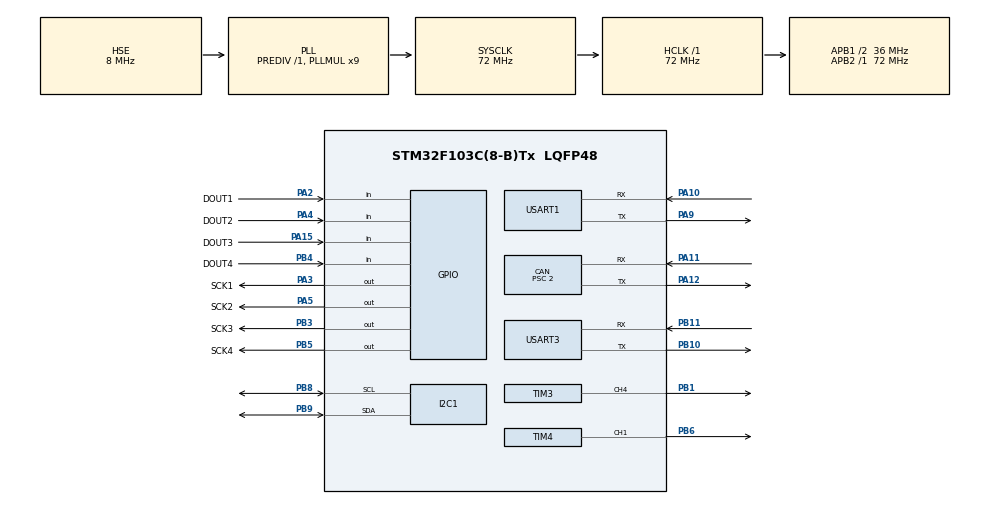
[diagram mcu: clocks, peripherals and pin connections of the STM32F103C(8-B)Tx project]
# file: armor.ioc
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CAN.BS1=CAN_BS1_15TQ
CAN.BS2=CAN_BS2_2TQ
CAN.CalculateBaudRate=1000000
CAN.CalculateTimeBit=1000
CAN.CalculateTimeQuantum=55.55555555555556
CAN.Prescaler=2
Dma.Request0=USART1_RX
Dma.Request1=USART1_TX
Dma.Request2=TIM3_CH4/UP
Dma.Request3=TIM4_CH1
Dma.TIM3_CH4/UP.2.Direction=DMA_MEMORY_TO_PERIPH
Dma.TIM3_CH4/UP.2.Instance=DMA1_Channel3
Dma.TIM3_CH4/UP.2.MemDataAlignment=DMA_MDATAALIGN_HALFWORD
Dma.TIM3_CH4/UP.2.MemInc=DMA_MINC_ENABLE
Dma.TIM3_CH4/UP.2.Mode=DMA_NORMAL
Dma.TIM3_CH4/UP.2.PeriphDataAlignment=DMA_PDATAALIGN_HALFWORD
Dma.TIM3_CH4/UP.2.PeriphInc=DMA_PINC_DISABLE
Dma.TIM3_CH4/UP.2.Priority=DMA_PRIORITY_HIGH
Dma.TIM4_CH1.3.Direction=DMA_MEMORY_TO_PERIPH
Dma.TIM4_CH1.3.Instance=DMA1_Channel1
Dma.TIM4_CH1.3.MemDataAlignment=DMA_MDATAALIGN_HALFWORD
Dma.TIM4_CH1.3.MemInc=DMA_MINC_ENABLE
Dma.TIM4_CH1.3.Mode=DMA_NORMAL
Dma.TIM4_CH1.3.PeriphDataAlignment=DMA_PDATAALIGN_HALFWORD
Dma.TIM4_CH1.3.PeriphInc=DMA_PINC_DISABLE
Dma.TIM4_CH1.3.Priority=DMA_PRIORITY_HIGH
Dma.USART1_RX.0.Direction=DMA_PERIPH_TO_MEMORY
Dma.USART1_RX.0.Instance=DMA1_Channel5
Dma.USART1_RX.0.MemDataAlignment=DMA_MDATAALIGN_BYTE
Dma.USART1_RX.0.MemInc=DMA_MINC_ENABLE
Dma.USART1_RX.0.Mode=DMA_NORMAL
Dma.USART1_RX.0.PeriphDataAlignment=DMA_PDATAALIGN_BYTE
Dma.USART1_RX.0.PeriphInc=DMA_PINC_DISABLE
Dma.USART1_RX.0.Priority=DMA_PRIORITY_LOW
Dma.USART1_TX.1.Direction=DMA_MEMORY_TO_PERIPH
Dma.USART1_TX.1.Instance=DMA1_Channel4
Dma.USART1_TX.1.MemDataAlignment=DMA_MDATAALIGN_BYTE
Dma.USART1_TX.1.MemInc=DMA_MINC_ENABLE
Dma.USART1_TX.1.Mode=DMA_NORMAL
Dma.USART1_TX.1.PeriphDataAlignment=DMA_PDATAALIGN_BYTE
Dma.USART1_TX.1.PeriphInc=DMA_PINC_DISABLE
Dma.USART1_TX.1.Priority=DMA_PRIORITY_LOW
Mcu.Family=STM32F1
Mcu.Name=STM32F103C(8-B)Tx
Mcu.Package=LQFP48
NVIC.DMA1_Channel1_IRQn=true\:0\:0\:false\:false\:true\:false\:true\:true
NVIC.DMA1_Channel3_IRQn=true\:0\:0\:false\:false\:true\:false\:true\:true
NVIC.DMA1_Channel4_IRQn=true\:0\:0\:false\:false\:true\:false\:true\:true
NVIC.DMA1_Channel5_IRQn=true\:0\:0\:false\:false\:true\:false\:true\:true
NVIC.PriorityGroup=NVIC_PRIORITYGROUP_4
NVIC.USART1_IRQn=true\:0\:0\:false\:false\:true\:true\:true\:true
PA10.Mode=Asynchronous
PA10.Signal=USART1_RX
PA11.Mode=CAN_Activate
PA11.Signal=CAN_RX
PA12.Mode=CAN_Activate
PA12.Signal=CAN_TX
PA13.Mode=Serial_Wire
PA13.Signal=SYS_JTMS-SWDIO
PA14.Mode=Serial_Wire
PA14.Signal=SYS_JTCK-SWCLK
PA15.GPIO_Label=DOUT3
PA15.Signal=GPIO_Input
PA2.GPIO_Label=DOUT1
PA2.GPIO_PuPd=GPIO_NOPULL
PA2.Signal=GPIO_Input
PA3.GPIO_Label=SCK1
PA3.GPIO_Speed=GPIO_SPEED_FREQ_LOW
PA3.Signal=GPIO_Output
PA4.GPIO_Label=DOUT2
PA4.GPIO_PuPd=GPIO_NOPULL
PA4.Signal=GPIO_Input
PA5.GPIO_Label=SCK2
PA5.GPIO_Speed=GPIO_SPEED_FREQ_LOW
PA5.Signal=GPIO_Output
PA9.Mode=Asynchronous
PA9.Signal=USART1_TX
PB1.Signal=S_TIM3_CH4
PB10.Mode=Asynchronous
PB10.Signal=USART3_TX
PB11.Mode=Asynchronous
PB11.Signal=USART3_RX
PB3.GPIO_Label=SCK3
PB3.PinState=GPIO_PIN_SET
PB3.Signal=GPIO_Output
PB4.GPIO_Label=DOUT4
PB4.Signal=GPIO_Input
PB5.GPIO_Label=SCK4
PB5.Signal=GPIO_Output
PB6.Signal=S_TIM4_CH1
PB8.Mode=I2C
PB8.Signal=I2C1_SCL
PB9.Mode=I2C
PB9.Signal=I2C1_SDA
PD0-OSC_IN.Mode=HSE-External-Oscillator
PD0-OSC_IN.Signal=RCC_OSC_IN
PD1-OSC_OUT.Mode=HSE-External-Oscillator
PD1-OSC_OUT.Signal=RCC_OSC_OUT
ProjectManager.HeapSize=0x2000
ProjectManager.StackSize=0x2000
ProjectManager.TargetToolchain=CMake
RCC.AHBFreq_Value=72000000
RCC.APB1CLKDivider=RCC_HCLK_DIV2
RCC.APB1Freq_Value=36000000
RCC.APB1TimFreq_Value=72000000
RCC.APB2Freq_Value=72000000
RCC.APB2TimFreq_Value=72000000
RCC.HCLKFreq_Value=72000000
RCC.PLLMUL=RCC_PLL_MUL9
RCC.PLLSourceVirtual=RCC_PLLSOURCE_HSE
RCC.SYSCLKFreq_VALUE=72000000
RCC.SYSCLKSource=RCC_SYSCLKSOURCE_PLLCLK
RCC.USBFreq_Value=72000000
SH.S_TIM3_CH4.0=TIM3_CH4,PWM Generation4 CH4
SH.S_TIM4_CH1.0=TIM4_CH1,PWM Generation1 CH1
TIM3.Channel-PWM\ Generation4\ CH4=TIM_CHANNEL_4
TIM3.Period=89
TIM4.Channel-PWM\ Generation1\ CH1=TIM_CHANNEL_1
TIM4.Period=89
USART1.VirtualMode=VM_ASYNC
USART3.VirtualMode=VM_ASYNC
VP_TIM3_VS_ClockSourceINT.Mode=Internal
VP_TIM4_VS_ClockSourceINT.Mode=Internal
board=custom

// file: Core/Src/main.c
/* USER CODE BEGIN Header */
/**
  ******************************************************************************
  * @file           : main.c
  * @brief          : Main program body
  ******************************************************************************
  * @attention
  *
  * Copyright (c) 2026 STMicroelectronics.
  * All rights reserved.
  *
  * This software is licensed under terms that can be found in the LICENSE file
  * in the root directory of this software component.
  * If no LICENSE file comes with this software, it is provided AS-IS.
  *
  ******************************************************************************
  */
/* USER CODE END Header */
#include "main.h"
#include "can.h"
#include "dma.h"
#include "i2c.h"
#include "tim.h"
#include "usart.h"
#include "gpio.h"

/* USER CODE BEGIN Includes */
#include "bsp_dwt.h"
#include "hx711.h"
#include "sk6812.h"
/* USER CODE END Includes */

void SystemClock_Config(void);

int main(void)
{

  /* MCU Configuration--------------------------------------------------------*/

  /* Reset of all peripherals, Initializes the Flash interface and the Systick. */
  HAL_Init();

  /* Configure the system clock */
  SystemClock_Config();

  /* Initialize all configured peripherals */
  MX_GPIO_Init();
  MX_DMA_Init();
  MX_I2C1_Init();
  MX_TIM3_Init();
  MX_TIM4_Init();
  MX_USART1_UART_Init();
  MX_CAN_Init();
  MX_USART3_UART_Init();
  /* USER CODE BEGIN 2 */
  DWT_Init(72);
  SK6812_Init();
  uint8_t send_data[] = {0x00};
  /* USER CODE END 2 */

  /* Infinite loop */
  /* USER CODE BEGIN WHILE */
  while (1)
  {
    const uint8_t hit = get_hit();
    if (hit)
      send_data[0] = 0x01;
    else
      send_data[0] = 0x00;
    SK6812_LEDS_Task(hit);
    HAL_UART_Transmit(&huart1, send_data, sizeof(send_data), 100);

    // printf_hx711_data();
    // HAL_Delay(50);
    /* USER CODE END WHILE */

  }
}

void SystemClock_Config(void)
{
  RCC_OscInitTypeDef RCC_OscInitStruct = {0};
  RCC_ClkInitTypeDef RCC_ClkInitStruct = {0};

  /** Initializes the RCC Oscillators according to the specified parameters
  * in the RCC_OscInitTypeDef structure.
  */
  RCC_OscInitStruct.OscillatorType = RCC_OSCILLATORTYPE_HSE;
  RCC_OscInitStruct.HSEState = RCC_HSE_ON;
  RCC_OscInitStruct.HSEPredivValue = RCC_HSE_PREDIV_DIV1;
  RCC_OscInitStruct.HSIState = RCC_HSI_ON;
  RCC_OscInitStruct.PLL.PLLState = RCC_PLL_ON;
  RCC_OscInitStruct.PLL.PLLSource = RCC_PLLSOURCE_HSE;
  RCC_OscInitStruct.PLL.PLLMUL = RCC_PLL_MUL9;
  if (HAL_RCC_OscConfig(&RCC_OscInitStruct) != HAL_OK)
  {
    Error_Handler();
  }

  /** Initializes the CPU, AHB and APB buses clocks
  */
  RCC_ClkInitStruct.ClockType = RCC_CLOCKTYPE_HCLK|RCC_CLOCKTYPE_SYSCLK
                              |RCC_CLOCKTYPE_PCLK1|RCC_CLOCKTYPE_PCLK2;
  RCC_ClkInitStruct.SYSCLKSource = RCC_SYSCLKSOURCE_PLLCLK;
  RCC_ClkInitStruct.AHBCLKDivider = RCC_SYSCLK_DIV1;
  RCC_ClkInitStruct.APB1CLKDivider = RCC_HCLK_DIV2;
  RCC_ClkInitStruct.APB2CLKDivider = RCC_HCLK_DIV1;

  if (HAL_RCC_ClockConfig(&RCC_ClkInitStruct, FLASH_LATENCY_2) != HAL_OK)
  {
    Error_Handler();
  }
}

void Error_Handler(void)
{
  __disable_irq();
  while (1)
  {
  }
}
